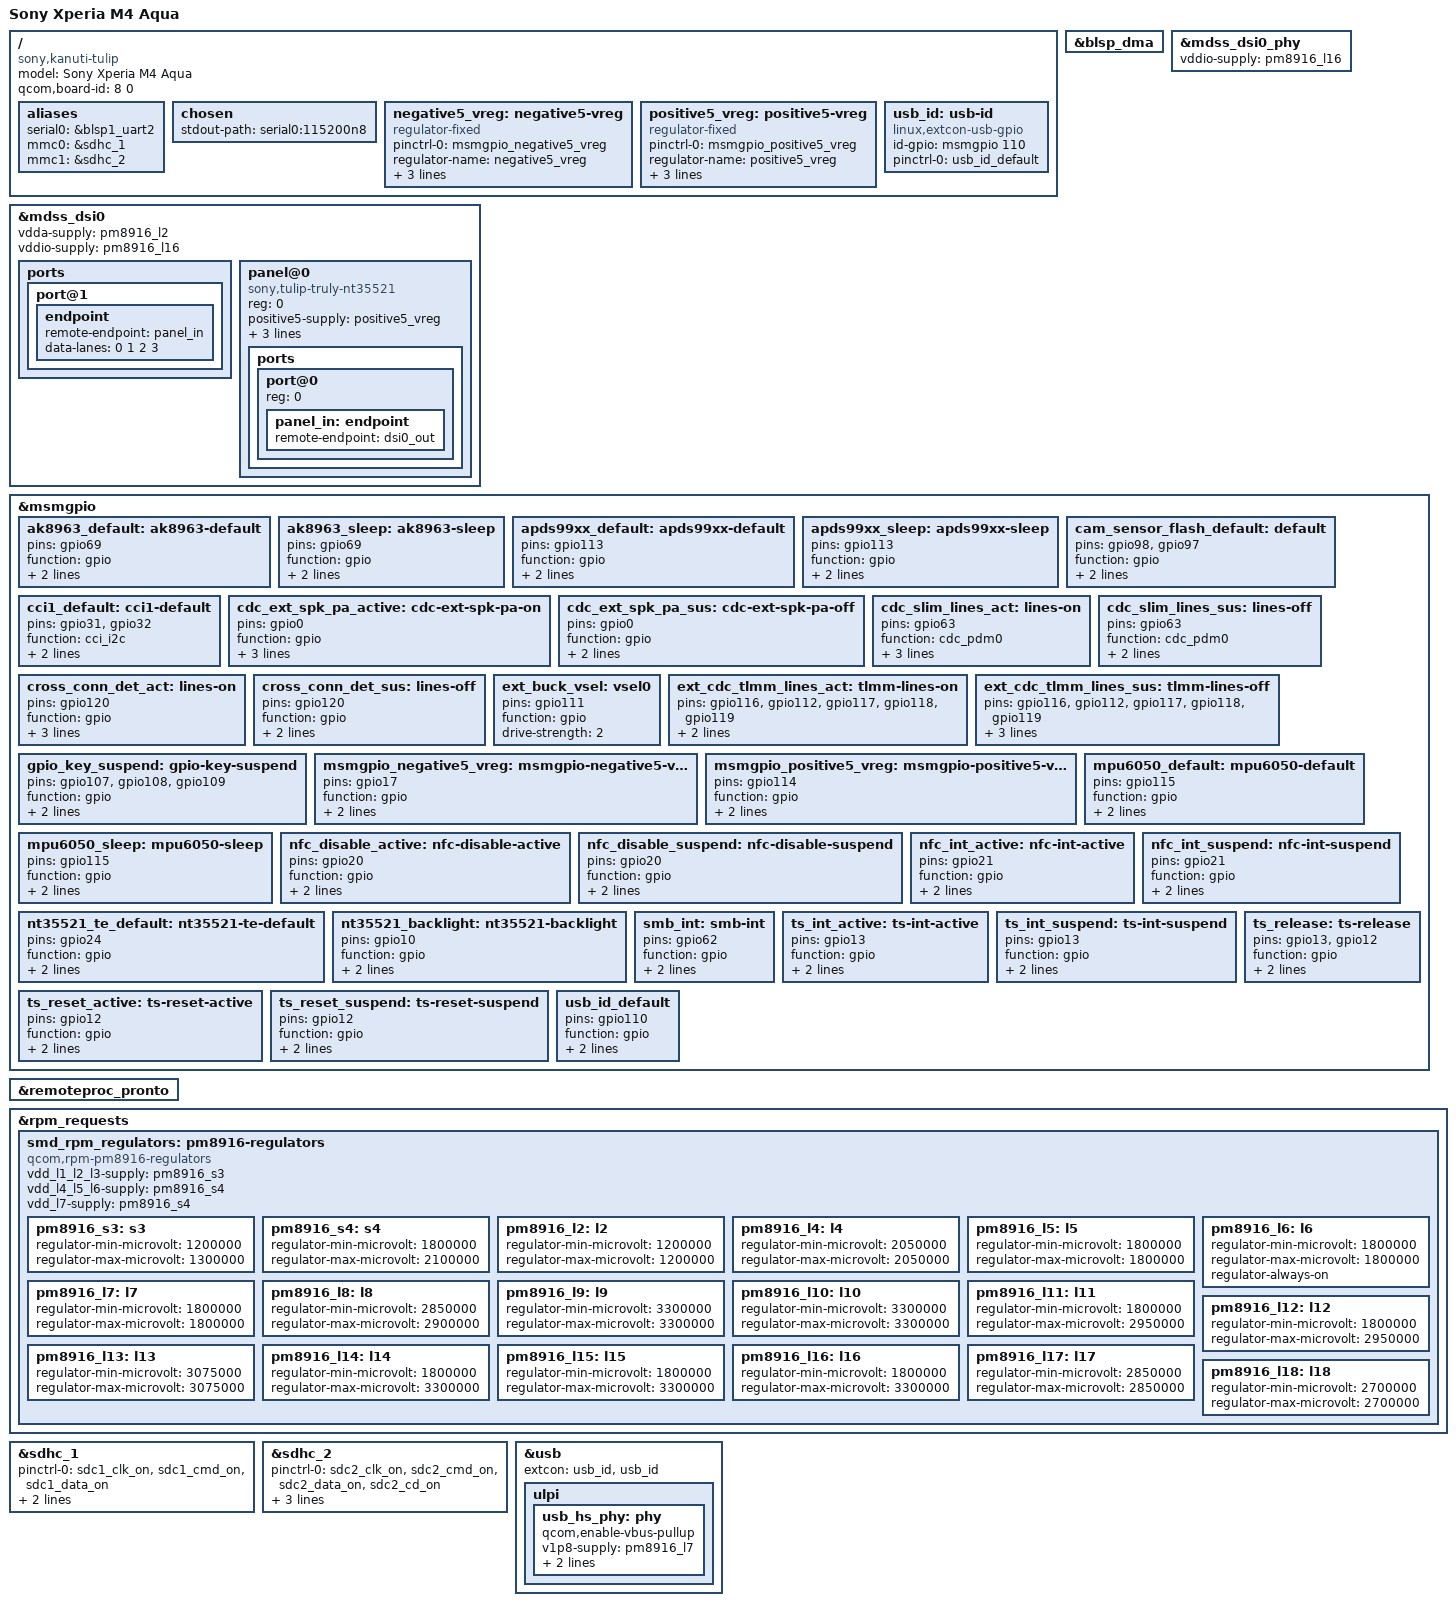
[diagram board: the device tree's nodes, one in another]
// SPDX-License-Identifier: GPL-2.0
/*
 * Copyright (c) 2015, The Linux Foundation. All rights reserved.
 * Copyright (c) 2022, Bryan O'Donoghue.
 *
 */

/dts-v1/;

#include "msm8939.dtsi"
#include "pm8916.dtsi"
#include <dt-bindings/gpio/gpio.h>
#include <dt-bindings/pinctrl/qcom,pmic-gpio.h>

/ {
	model = "Sony Xperia M4 Aqua";
	compatible = "sony,kanuti-tulip", "qcom,msm8939";
	qcom,board-id = <8 0>;

	aliases {
		serial0 = &blsp1_uart2;
		mmc0 = &sdhc_1; /* SDC1 eMMC slot */
		mmc1 = &sdhc_2; /* SDC2 SD card slot */
	};

	chosen {
		stdout-path = "serial0:115200n8";
	};

	negative5_vreg: negative5-vreg {
		compatible = "regulator-fixed";
		pinctrl-names = "default";
		pinctrl-0 = <&msmgpio_negative5_vreg>;
		regulator-name = "negative5_vreg";
		gpios = <&msmgpio 17 GPIO_ACTIVE_LOW>;
		startup-delay-us = <0>;
		enable-active-low;
	};

	positive5_vreg: positive5-vreg {
		compatible = "regulator-fixed";
		pinctrl-names = "default";
		pinctrl-0 = <&msmgpio_positive5_vreg>;
		regulator-name = "positive5_vreg";
		gpios = <&msmgpio 114 GPIO_ACTIVE_LOW>;
		startup-delay-us = <0>;
		enable-active-low;
	};

	usb_id: usb-id {
		compatible = "linux,extcon-usb-gpio";
		id-gpio = <&msmgpio 110 GPIO_ACTIVE_HIGH>;
		pinctrl-names = "default";
		pinctrl-0 = <&usb_id_default>;
	};
};

&blsp_dma {
	status = "okay";
};

&mdss_dsi0 {
	#address-cells = <1>;
	#size-cells = <0>;
	vdda-supply = <&pm8916_l2>;
	vddio-supply = <&pm8916_l16>;
	status = "okay";

	ports {
		port@1 {
			endpoint {
				remote-endpoint = <&panel_in>;
				data-lanes = <0 1 2 3>;
			};
		};
	};

	panel@0 {
		compatible = "sony,tulip-truly-nt35521";
		reg = <0>;
		positive5-supply = <&positive5_vreg>;
		negative5-supply = <&negative5_vreg>;
		reset-gpios = <&msmgpio 25 GPIO_ACTIVE_LOW>;
		enable-gpios = <&msmgpio 10 GPIO_ACTIVE_LOW>;

		ports {
			#address-cells = <1>;
			#size-cells = <0>;

			port@0 {
				reg = <0>;
				panel_in: endpoint {
					remote-endpoint = <&dsi0_out>;
				};
			};
		};

	};
};

&mdss_dsi0_phy {
	vddio-supply = <&pm8916_l16>;
	status = "okay";
};

&msmgpio {

	ak8963_default: ak8963-default {
		pins = "gpio69";
		function = "gpio";
		drive-strength = <6>;
		bias-pull-up;
	};

	ak8963_sleep: ak8963-sleep {
		pins = "gpio69";
		function = "gpio";
		drive-strength = <2>;
		bias-pull-down;
	};

	/* Ambient light and proximity sensor apds9930 and apds9900 */
	apds99xx_default: apds99xx-default {
		pins = "gpio113";
		function = "gpio";
		drive-strength = <6>;
		bias-pull-up;
	};

	apds99xx_sleep: apds99xx-sleep {
		pins = "gpio113";
		function = "gpio";
		drive-strength = <2>;
		bias-pull-down;
	};

	cam_sensor_flash_default: default {
		pins = "gpio98", "gpio97";
		function = "gpio";
		bias-disable;
		drive-strength = <2>;
	};

	cci1_default: cci1-default {
		pins = "gpio31", "gpio32";
		function = "cci_i2c";
		drive-strength = <2>;
		bias-disable;
	};

	cdc_ext_spk_pa_active: cdc-ext-spk-pa-on {
		pins = "gpio0";
		function = "gpio";
		drive-strength = <8>;
		output-low;
		bias-pull-none;
	};

	cdc_ext_spk_pa_sus: cdc-ext-spk-pa-off {
		pins = "gpio0";
		function = "gpio";
		drive-strength = <2>;
		bias-disable;
	};

	cdc_slim_lines_act: lines-on {
		pins = "gpio63";
		function = "cdc_pdm0";
		drive-strength = <8>;
		output-high;
		bias-pull-none;
	};

	cdc_slim_lines_sus: lines-off {
		pins = "gpio63";
		function = "cdc_pdm0";
		drive-strength = <2>;
		bias-disable;
	};

	cross_conn_det_act: lines-on {
		pins = "gpio120";
		function = "gpio";
		drive-strength = <8>;
		output-low;
		bias-pull-down;
	};

	cross_conn_det_sus: lines-off {
		pins = "gpio120";
		function = "gpio";
		drive-strength = <2>;
		bias-pull-down;
	};

	ext_buck_vsel: vsel0 {
		pins = "gpio111";
		function = "gpio";
		drive-strength = <2>;
	};

	ext_cdc_tlmm_lines_act: tlmm-lines-on {
		pins = "gpio116", "gpio112", "gpio117", "gpio118", "gpio119";
		function = "gpio";
		drive-strength = <8>;
	};

	ext_cdc_tlmm_lines_sus: tlmm-lines-off {
		pins = "gpio116", "gpio112", "gpio117", "gpio118", "gpio119";
		function = "gpio";
		drive-strength = <2>;
		bias-disable;
	};

	gpio_key_suspend: gpio-key-suspend {
		pins = "gpio107", "gpio108", "gpio109";
		function = "gpio";
		drive-strength = <2>;
		bias-pull-up;
	};

	msmgpio_negative5_vreg: msmgpio-negative5-vreg {
		pins = "gpio17";
		function = "gpio";
		output-low;
		bias-pull-none;
	};

	msmgpio_positive5_vreg: msmgpio-positive5-vreg {
		pins = "gpio114";
		function = "gpio";
		output-low;
		bias-pull-none;
	};

	/* Gyroscope and accelerometer sensor combo */
	mpu6050_default: mpu6050-default {
		pins = "gpio115";
		function = "gpio";
		drive-strength = <6>;
		bias-pull-up;
	};

	mpu6050_sleep: mpu6050-sleep {
		pins = "gpio115";
		function = "gpio";
		drive-strength = <2>;
		bias-pull-down;
	};

	nfc_disable_active: nfc-disable-active {
		pins = "gpio20";
		function = "gpio";
		drive-strength = <6>;
		bias-pull-up;
	};

	nfc_disable_suspend: nfc-disable-suspend {
		pins = "gpio20";
		function = "gpio";
		drive-strength = <6>;
		bias-disable;
	};

	nfc_int_active: nfc-int-active {
		pins = "gpio21";
		function = "gpio";
		drive-strength = <6>;
		bias-pull-up;
	};

	nfc_int_suspend: nfc-int-suspend {
		pins = "gpio21";
		function = "gpio";
		drive-strength = <6>;
		bias-pull-up;
	};

	nt35521_te_default: nt35521-te-default {
		pins = "gpio24";
		function = "gpio";
		drive-strength = <6>;
		bias-pull-down;
	};

	nt35521_backlight: nt35521-backlight {
		pins = "gpio10";
		function = "gpio";
		drive-strength = <6>;
		bias-pull-down;
	};

	smb_int: smb-int {
		pins = "gpio62";
		function = "gpio";
		drive-strength = <2>;
		bias-pull-up;
	};

	/* add pingrp for touchscreen */
	ts_int_active: ts-int-active {
		pins = "gpio13";
		function = "gpio";
		drive-strength = <16>;
		bias-pull-up;
	};

	ts_int_suspend: ts-int-suspend {
		pins = "gpio13";
		function = "gpio";
		drive-strength = <2>;
		bias-pull-down;
	};

	ts_reset_active: ts-reset-active {
		pins = "gpio12";
		function = "gpio";
		drive-strength = <16>;
		bias-pull-up;
	};

	ts_reset_suspend: ts-reset-suspend {
		pins = "gpio12";
		function = "gpio";
		drive-strength = <2>;
		bias-pull-down;
	};

	ts_release: ts-release {
		pins = "gpio13", "gpio12";
		function = "gpio";
		drive-strength = <2>;
		bias-pull-down;
	};

	usb_id_default: usb_id_default {
		pins = "gpio110";
		function = "gpio";

		drive-strength = <8>;
		bias-pull-up;
	};
};

&remoteproc_pronto {
	status = "okay";
};

&rpm_requests {
	smd_rpm_regulators: pm8916-regulators {
		compatible = "qcom,rpm-pm8916-regulators";
		vdd_l1_l2_l3-supply = <&pm8916_s3>;
		vdd_l4_l5_l6-supply = <&pm8916_s4>;
		vdd_l7-supply = <&pm8916_s4>;

		pm8916_s3: s3 {
			regulator-min-microvolt = <1200000>;
			regulator-max-microvolt = <1300000>;
		};

		pm8916_s4: s4 {
			regulator-min-microvolt = <1800000>;
			regulator-max-microvolt = <2100000>;
		};

		pm8916_l2: l2 {
			regulator-min-microvolt = <1200000>;
			regulator-max-microvolt = <1200000>;
		};

		pm8916_l4: l4 {
			regulator-min-microvolt = <2050000>;
			regulator-max-microvolt = <2050000>;
		};

		pm8916_l5: l5 {
			regulator-min-microvolt = <1800000>;
			regulator-max-microvolt = <1800000>;
		};

		pm8916_l6: l6 {
			regulator-min-microvolt = <1800000>;
			regulator-max-microvolt = <1800000>;
			regulator-always-on;
		};

		pm8916_l7: l7 {
			regulator-min-microvolt = <1800000>;
			regulator-max-microvolt = <1800000>;
		};

		pm8916_l8: l8 {
			regulator-min-microvolt = <2850000>;
			regulator-max-microvolt = <2900000>;
		};

		pm8916_l9: l9 {
			regulator-min-microvolt = <3300000>;
			regulator-max-microvolt = <3300000>;
		};

		pm8916_l10: l10 {
			regulator-min-microvolt = <3300000>;
			regulator-max-microvolt = <3300000>;
		};

		pm8916_l11: l11 {
			regulator-min-microvolt = <1800000>;
			regulator-max-microvolt = <2950000>;
		};

		pm8916_l12: l12 {
			regulator-min-microvolt = <1800000>;
			regulator-max-microvolt = <2950000>;
		};

		pm8916_l13: l13 {
			regulator-min-microvolt = <3075000>;
			regulator-max-microvolt = <3075000>;
		};

		pm8916_l14: l14 {
			regulator-min-microvolt = <1800000>;
			regulator-max-microvolt = <3300000>;
		};

		pm8916_l15: l15 {
			regulator-min-microvolt = <1800000>;
			regulator-max-microvolt = <3300000>;
		};

		pm8916_l16: l16 {
			regulator-min-microvolt = <1800000>;
			regulator-max-microvolt = <3300000>;
		};

		pm8916_l17: l17 {
			regulator-min-microvolt = <2850000>;
			regulator-max-microvolt = <2850000>;
		};

		pm8916_l18: l18 {
			regulator-min-microvolt = <2700000>;
			regulator-max-microvolt = <2700000>;
		};
	};
};

&sdhc_1 {
	pinctrl-names = "default", "sleep";
	pinctrl-0 = <&sdc1_clk_on &sdc1_cmd_on &sdc1_data_on>;
	pinctrl-1 = <&sdc1_clk_off &sdc1_cmd_off &sdc1_data_off>;
	status = "okay";
};

&sdhc_2 {
	pinctrl-names = "default", "sleep";
	pinctrl-0 = <&sdc2_clk_on &sdc2_cmd_on &sdc2_data_on &sdc2_cd_on>;
	pinctrl-1 = <&sdc2_clk_off &sdc2_cmd_off &sdc2_data_off &sdc2_cd_off>;
	cd-gpios = <&msmgpio 38 GPIO_ACTIVE_HIGH>;
	status = "okay";
};

&usb {
	status = "okay";
	extcon = <&usb_id>, <&usb_id>;

	ulpi {
		usb_hs_phy: phy {
			qcom,enable-vbus-pullup;
			v1p8-supply = <&pm8916_l7>;
			v3p3-supply = <&pm8916_l13>;
		};
	};
};

&usb_hs_phy {
	extcon = <&usb_id>;
};
